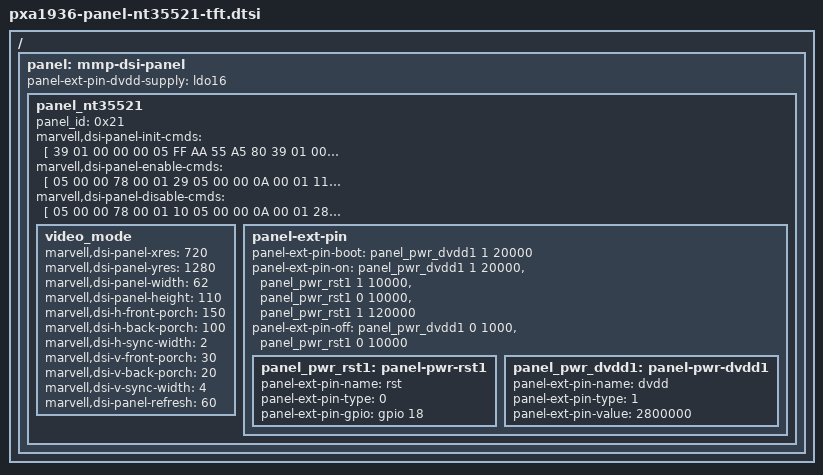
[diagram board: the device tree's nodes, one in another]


/ {
	panel: mmp-dsi-panel {
		panel-ext-pin-dvdd-supply = <&ldo16>;
		panel_nt35521 {
			/*
			 * BACKLIGHT CONTROL BY GPIO
			 */
			panel_id = <0x21>;
			/*
			 * DSI PACKET HEADER INFO
			 * @ data type : 1byte
			 * @ command type : 1byte
			 * @ delay(msec) : 2byte
			 * @ size of data : 2byte
			 */
			marvell,dsi-panel-init-cmds = [
	#if 0 
                            39 01 00 00 00 05 FF AA 55 A5 80                                                              
                            39 01 00 00 00 03 6F 11 00                                                                     
                            39 01 00 00 00 03 F7 20 00                                                                     
                            39 01 00 00 00 02 6F 1E                                                                        
                            39 01 00 00 00 02 FA 20                                                                        
                            39 01 00 00 00 02 6F 1E                                                                        
                            39 01 00 00 00 02 FA 00                                                                        
                            39 01 00 00 00 02 6F 1F                                                                        
                            39 01 00 00 00 02 FA 00                                                                        
                            39 01 00 00 00 02 6F 11                                                                        
                            39 01 00 00 00 02 F3 01                                                                        
                            39 01 00 00 00 06 F0 55 AA 52 08 00                                                          
                            39 01 00 00 00 06 BD 01 A0 0C 08 01                                                          
                            39 01 00 00 00 02 6F 02                                                                      
                            39 01 00 00 00 02 B8 01                                                                  
                            39 01 00 00 00 03 B1 68 21                                                                   
                            39 01 00 00 00 03 BB 11 11                                                                   
                            39 01 00 00 00 03 BC 00 00                                                                   
                            39 01 00 00 00 02 B6 01                                                                     
                            39 01 00 00 00 06 F0 55 AA 52 08 01                                                         
                            39 01 00 00 00 03 B0 09 09                                                                   
                            39 01 00 00 00 03 B1 09 09                                                                   
                            39 01 00 00 00 03 BC 68 00                                                                   
                            39 01 00 00 00 03 BD 68 00                                                                   
                            39 01 00 00 00 02 CA 00                                                                      
                            39 01 00 00 00 02 C0 04                                                                      
                            39 01 00 00 00 03 B5 03 03                                                                  
                            39 01 00 00 00 02 BE 53                                                           
                            39 01 00 00 00 03 B3 19 19                                                                   
                            39 01 00 00 00 03 B4 0F 0F                                                                   
                            39 01 00 00 00 03 B9 26 26
                            39 01 00 00 00 03 BA 14 14
                            39 01 00 00 00 06 F0 55 AA 52 08 02                                                         
                            39 01 00 00 00 02 EE 01
                            39 01 00 00 00 11 B0 00 00 00 58 00 88 00 A7 00 C0 00 E8 01 08 01 3C   
                            39 01 00 00 00 11 B1 01 63 01 A4 01 D6 02 26 02 67 02 69 02 A5 02 E3   
                            39 01 00 00 00 11 B2 03 09 03 3A 03 5E 03 8A 03 A5 03 C4 03 D8 03 ED   
                            39 01 00 00 00 05 B3 03 F7 03 FB                                                             
                            39 01 00 00 00 02 6F 02                                                                      
                            39 01 00 00 00 02 F7 47                                                                      
                            39 01 00 00 00 02 6F 0A                                                                      
                            39 01 00 00 00 02 F7 02                                                                      
                            39 01 00 00 00 02 6F 17                                                                      
                            39 01 00 00 00 02 F4 70                                                                      
                            39 01 00 00 00 02 6F 11                                                                      
                            39 01 00 00 00 02 F3 01
                            39 01 00 00 00 06 F0 55 AA 52 08 06                                                         
                            39 01 00 00 00 03 B0 12 10                                                                 
                            39 01 00 00 00 03 B1 18 16                                                                 
                            39 01 00 00 00 03 B2 00 02                                                                 
                            39 01 00 00 00 03 B3 31 31                                                                 
                            39 01 00 00 00 03 B4 31 34                                                                 
                            39 01 00 00 00 03 B5 34 31                                                                 
                            39 01 00 00 00 03 B6 31 33                                                                 
                            39 01 00 00 00 03 B7 33 33                                                                 
                            39 01 00 00 00 03 B8 31 08                                                                 
                            39 01 00 00 00 03 B9 2E 2D                                                                 
                            39 01 00 00 00 03 BA 2D 2E                                                                 
                            39 01 00 00 00 03 BB 09 31                                                                 
                            39 01 00 00 00 03 BC 33 33                                                                 
                            39 01 00 00 00 03 BD 33 31                                                                 
                            39 01 00 00 00 03 BE 31 34                                                                 
                            39 01 00 00 00 03 BF 34 31                                                                 
                            39 01 00 00 00 03 C0 31 31                                                                 
                            39 01 00 00 00 03 C1 03 01                                                                 
                            39 01 00 00 00 03 C2 17 19                                                                 
                            39 01 00 00 00 03 C3 11 13                                                                 
                            39 01 00 00 00 03 E5 31 31                                                                 
                            39 01 00 00 00 03 C4 17 19                                                                 
                            39 01 00 00 00 03 C5 11 13                                                                 
                            39 01 00 00 00 03 C6 03 01                                                                 
                            39 01 00 00 00 03 C7 31 31                                                                 
                            39 01 00 00 00 03 C8 31 34                                                                 
                            39 01 00 00 00 03 C9 34 31                                                                 
                            39 01 00 00 00 03 CA 31 33                                                                 
                            39 01 00 00 00 03 CB 33 33                                                                 
                            39 01 00 00 00 03 CC 31 09                                                                 
                            39 01 00 00 00 03 CD 2D 2E                                                                 
                            39 01 00 00 00 03 CE 2E 2D                                                                 
                            39 01 00 00 00 03 CF 08 31                                                                 
                            39 01 00 00 00 03 D0 33 33                                                                 
                            39 01 00 00 00 03 D1 33 31                                                                 
                            39 01 00 00 00 03 D2 31 34                                                                 
                            39 01 00 00 00 03 D3 34 31                                                                 
                            39 01 00 00 00 03 D4 31 31                                                                 
                            39 01 00 00 00 03 D5 00 02                                                                 
                            39 01 00 00 00 03 D6 12 10                                                                 
                            39 01 00 00 00 03 D7 18 16                                                                 
                            39 01 00 00 00 06 D8 00 00 00 00 00                                                          
                            39 01 00 00 00 06 D9 00 00 00 00 00                                                          
                            39 01 00 00 00 02 E7 00
                            39 01 00 00 00 06 F0 55 AA 52 08 05                                                         
                            39 01 00 00 00 02 ED 30
                            39 01 00 00 00 06 F0 55 AA 52 08 03                                                         
                            39 01 00 00 00 03 B1 00 00                                                                   
                            39 01 00 00 00 03 B0 00 00
                            39 01 00 00 00 06 F0 55 AA 52 08 05                                                          
                            39 01 00 00 00 02 E5 00                                                                  
                            39 01 00 00 00 06 F0 55 AA 52 08 05                                                         
                            39 01 00 00 00 03 B0 17 06                                                                  
                            39 01 00 00 00 02 B8 00                                                                     
                            39 01 00 00 00 06 BD 03 03 01 00 03                                                         
                            39 01 00 00 00 03 B1 17 06                                                                   
                            39 01 00 00 00 03 B9 00 03                                                                   
                            39 01 00 00 00 03 B2 17 06                                                                   
                            39 01 00 00 00 03 BA 00 00                                                                   
                            39 01 00 00 00 03 B3 17 06                                                                   
                            39 01 00 00 00 03 BB 00 00                                                                   
                            39 01 00 00 00 03 B4 17 06                                                                   
                            39 01 00 00 00 03 B5 17 06                                                                   
                            39 01 00 00 00 03 B6 17 06                                                                   
                            39 01 00 00 00 03 B7 17 06                                                                   
                            39 01 00 00 00 03 BC 00 03                                                                   
                            39 01 00 00 00 02 E5 06                                                                      
                            39 01 00 00 00 02 E6 06                                                                      
                            39 01 00 00 00 02 E7 06                                                                      
                            39 01 00 00 00 02 E8 06                                                                      
                            39 01 00 00 00 02 E9 06                                                                      
                            39 01 00 00 00 02 EA 06                                                                      
                            39 01 00 00 00 02 EB 06                                                                      
                            39 01 00 00 00 02 EC 06
                            39 01 00 00 00 06 F0 55 AA 52 08 05                                                         
                            39 01 00 00 00 02 C0 0B                                                                  
                            39 01 00 00 00 02 C1 09                                                                  
                            39 01 00 00 00 02 C2 0B                                                                    
                            39 01 00 00 00 02 C3 09
                            39 01 00 00 00 06 F0 55 AA 52 08 03                                                          
                            39 01 00 00 00 06 B2 05 00 00 00 90                                        
                            39 01 00 00 00 06 B3 05 00 00 00 90                                                          
                            39 01 00 00 00 06 B4 05 00 00 00 90                                                          
                            39 01 00 00 00 06 B5 05 00 00 00 90
                            39 01 00 00 00 06 F0 55 AA 52 08 05                                                          
                            39 01 00 00 00 02 C4 10                                                                      
                            39 01 00 00 00 02 C5 10                                                                      
                            39 01 00 00 00 02 C6 10                                                                      
                            39 01 00 00 00 02 C7 10
                            39 01 00 00 00 06 F0 55 AA 52 08 03                                                          
                            39 01 00 00 00 06 B6 05 00 00 00 00                                       
                            39 01 00 00 00 06 B7 05 00 00 00 00                                                          
                            39 01 00 00 00 06 B8 05 00 00 00 00                                                          
                            39 01 00 00 00 06 B9 05 00 00 00 00
                            39 01 00 00 00 06 F0 55 AA 52 08 05                                                          
                            39 01 00 00 00 03 C8 07 20                                                                   
                            39 01 00 00 00 03 C9 03 20                                                                   
                            39 01 00 00 00 03 CA 07 00                                                                   
                            39 01 00 00 00 03 CB 03 00
                            39 01 00 00 00 06 F0 55 AA 52 08 03                                                          
                            39 01 00 00 00 06 BA 44 00 00 00 70                                
                            39 01 00 00 00 06 BB 44 00 00 00 70                                                     
                            39 01 00 00 00 06 BC 44 00 00 00 70                                                      
                            39 01 00 00 00 06 BD 44 00 00 00 70
                            39 01 00 00 00 06 F0 55 AA 52 08 05                                                          
                            39 01 00 00 00 06 D1 00 05 00 07 10                                                          
                            39 01 00 00 00 06 D2 00 05 04 07 10                                                          
                            39 01 00 00 00 06 D3 00 00 0A 07 10                                                          
                            39 01 00 00 00 06 D4 00 00 0A 07 10
                            39 01 00 00 00 06 F0 55 AA 52 08 05                                                          
                            39 01 00 00 00 08 D0 00 00 00 00 00 00 00                                               
                            39 01 00 00 00 0C D5 00 00 00 00 00 00 00 00 00 00 00                            
                            39 01 00 00 00 0C D6 00 00 00 00 00 00 00 00 00 00 00                            
                            39 01 00 00 00 0C D7 00 00 00 00 00 00 00 00 00 00 00                            
                            39 01 00 00 00 06 D8 00 00 00 00 00
                            39 01 00 00 00 06 F0 55 AA 52 08 03                                                          
                            39 01 00 00 00 02 C4 60                                                                              
                            39 01 00 00 00 02 C5 40                                                                              
                            39 01 00 00 00 02 C6 60                                                                              
                            39 01 00 00 00 02 C7 40                                                                              
                            39 01 00 00 00 02 6F 01                                                                              
                            39 01 00 00 00 02 F9 46                                                                              
                            39 01 00 00 00 02 35 00                                                                              
                            39 01 00 00 00 02 55 90
#endif
#if 1 
				39 01 00 00 00 05 FF AA 55 A5 80
				39 01 00 00 00 03 6F 11 00
				39 01 00 00 00 03 F7 20 00
				39 01 00 00 00 02 6F 11
				39 01 00 00 00 02 F3 01
				39 01 00 00 00 06 F0 55 AA 52 08 00
				39 01 00 00 00 06 BD 01 A0 0C 08 01
				39 01 00 00 00 02 6F 02
				39 01 00 00 00 02 B8 01
				39 01 00 00 00 03 BB 11 11
				39 01 00 00 00 03 BC 00 00
				39 01 00 00 00 02 B6 06
				39 01 00 00 00 06 F0 55 AA 52 08 01
				39 01 00 00 00 03 B0 09 09
				39 01 00 00 00 03 B1 09 09
				39 01 00 00 00 03 BC 78 00
				39 01 00 00 00 03 BD 78 00
				39 01 00 00 00 02 C0 04
				39 01 00 00 00 03 B5 03 03
				39 01 00 00 00 02 BE 53
				39 01 00 00 00 03 B3 20 20
				39 01 00 00 00 03 B4 0F 0F
				39 01 00 00 00 03 B9 34 34
				39 01 00 00 00 03 BA 15 15
				39 01 00 00 00 06 F0 55 AA 52 08 02
				39 01 00 00 00 02 EE 01
				39 01 00 00 00 11 B0 00 00 00 58 00 88 00 A7 00 C0 00 E8 01 08 01 3C
				39 01 00 00 00 11 B1 01 63 01 A4 01 D6 02 26 02 67 02 69 02 A5 02 E3
				39 01 00 00 00 11 B2 03 09 03 3A 03 5E 03 8A 03 A5 03 C4 03 D8 03 ED
				39 01 00 00 00 05 B3 03 F7 03 FB
				39 01 00 00 00 02 6F 02
				39 01 00 00 00 02 F7 47
				39 01 00 00 00 02 6F 0A
				39 01 00 00 00 02 F7 02
				39 01 00 00 00 02 6F 17
				39 01 00 00 00 02 F4 60
				39 01 00 00 00 02 6F 29
				39 01 00 00 00 02 FA 01
				39 01 00 00 00 02 6F 11
				39 01 00 00 00 02 F3 01
				39 01 00 00 00 06 F0  55 AA 52 08 06
				39 01 00 00 00 03 B0  12 10
				39 01 00 00 00 03 B1  18 16
				39 01 00 00 00 03 B2  00 02
				39 01 00 00 00 03 B3  31 31
				39 01 00 00 00 03 B4  31 31
				39 01 00 00 00 03 B5  31 31
				39 01 00 00 00 03 B6  31 31
				39 01 00 00 00 03 B7  31 31
				39 01 00 00 00 03 B8  31 08
				39 01 00 00 00 03 B9  2E 2D
				39 01 00 00 00 03 BA  2D 2E
				39 01 00 00 00 03 BB  09 31
				39 01 00 00 00 03 BC  31 31
				39 01 00 00 00 03 BD  31 31
				39 01 00 00 00 03 BE  31 31
				39 01 00 00 00 03 BF  31 31
				39 01 00 00 00 03 C0  31 31
				39 01 00 00 00 03 C1  03 01
				39 01 00 00 00 03 C2  17 19
				39 01 00 00 00 03 C3  11 13
				39 01 00 00 00 03 E5  31 31
				39 01 00 00 00 03 C4  17 19
				39 01 00 00 00 03 C5  11 13
				39 01 00 00 00 03 C6  03 01
				39 01 00 00 00 03 C7  31 31
				39 01 00 00 00 03 C8  31 31
				39 01 00 00 00 03 C9  31 31
				39 01 00 00 00 03 CA  31 31
				39 01 00 00 00 03 CB  31 31
				39 01 00 00 00 03 CC  31 09
				39 01 00 00 00 03 CE  2E 2D
				39 01 00 00 00 03 CF  08 31
				39 01 00 00 00 03 D0  31 31
				39 01 00 00 00 03 D1  31 31
				39 01 00 00 00 03 D2  31 31
				39 01 00 00 00 03 D3  31 31
				39 01 00 00 00 03 D4  31 31
				39 01 00 00 00 03 D5  00 02
				39 01 00 00 00 03 D6  12 10
				39 01 00 00 00 03 D7  18 16
				39 01 00 00 00 06 D8  00 00 00 00 00
				39 01 00 00 00 06 D9  00 00 00 00 00
				39 01 00 00 00 02 E7  00
				39 01 00 00 00 06 F0  55 AA 52 08 05
				39 01 00 00 00 02 ED  30
				39 01 00 00 00 06 F0  55 AA 52 08 03
				39 01 00 00 00 03 B1  00 00
				39 01 00 00 00 03 B0  20 00
				39 01 00 00 00 06 F0  55 AA 52 08 05
				39 01 00 00 00 02 E5  00
				39 01 00 00 00 06 F0  55 AA 52 08 05
				39 01 00 00 00 03 B0  17 06
				39 01 00 00 00 02 B8  00
				39 01 00 00 00 06 BD  03 03 01 00 03
				39 01 00 00 00 03 B1  17 06
				39 01 00 00 00 03 B9  00 03
				39 01 00 00 00 03 B2  17 06
				39 01 00 00 00 03 BA  00 00
				39 01 00 00 00 03 B3  17 06
				39 01 00 00 00 03 BB  00 00
				39 01 00 00 00 03 B4  17 06
				39 01 00 00 00 03 B5  17 06
				39 01 00 00 00 03 B6  17 06
				39 01 00 00 00 03 B7  17 06
				39 01 00 00 00 03 BC  00 03
				39 01 00 00 00 02 E5  06
				39 01 00 00 00 02 E6  06
				39 01 00 00 00 02 E7  06
				39 01 00 00 00 02 E8  06
				39 01 00 00 00 02 E9  06
				39 01 00 00 00 02 EA  06
				39 01 00 00 00 02 EB  06
				39 01 00 00 00 02 EC  06
				39 01 00 00 00 06 F0  55 AA 52 08 05
				39 01 00 00 00 02 C0  0B
				39 01 00 00 00 02 C1  09
				39 01 00 00 00 02 C2  0B
				39 01 00 00 00 02 C3  09
				39 01 00 00 00 06 F0  55 AA 52 08 03
				39 01 00 00 00 06 B2  05 00 00 00 90
				39 01 00 00 00 06 B3  05 00 00 00 90
				39 01 00 00 00 06 B4  05 00 00 00 90
				39 01 00 00 00 06 B5  05 00 00 00 90
				39 01 00 00 00 06 F0  55 AA 52 08 05
				39 01 00 00 00 02 C4  10
				39 01 00 00 00 02 C5  10
				39 01 00 00 00 02 C6  10
				39 01 00 00 00 02 C7  10
				39 01 00 00 00 06 F0  55 AA 52 08 03
				39 01 00 00 00 06 B6  05 00 00 00 90
				39 01 00 00 00 06 B7  05 00 00 00 90
				39 01 00 00 00 06 B8  05 00 00 00 90
				39 01 00 00 00 06 B9  05 00 00 00 90
				39 01 00 00 00 06 F0  55 AA 52 08 05
				39 01 00 00 00 03 C8  08 20
				39 01 00 00 00 03 C9  04 20
				39 01 00 00 00 03 CA  07 00
				39 01 00 00 00 03 CB  03 00
				39 01 00 00 00 06 F0  55 AA 52 08 03
				39 01 00 00 00 06 BA  53 01 00 01 00
				39 01 00 00 00 06 BB  53 01 00 01 00
				39 01 00 00 00 06 BC  53 01 00 01 00
				39 01 00 00 00 06 BD  53 01 00 01 00
				39 01 00 00 00 06 F0  55 AA 52 08 05
				39 01 00 00 00 06 D1  00 05 00 07 10
				39 01 00 00 00 06 D2  00 05 04 07 10
				39 01 00 00 00 06 D3  00 00 0A 07 10
				39 01 00 00 00 06 D4  00 00 0A 07 10
				39 01 00 00 00 06 F0  55 AA 52 08 05
				39 01 00 00 00 08 D0  00 00 00 00 00 00 00
				39 01 00 00 00 0c D5  00 00 00 00 00 00 00 00 00 00 00
				39 01 00 00 00 0c D6  00 00 00 00 00 00 00 00 00 00 00
				39 01 00 00 00 0c D7  00 00 00 00 00 00 00 00 00 00 00
				39 01 00 00 00 06 D8  00 00 00 00 00
				39 01 00 00 00 06 F0  55 AA 52 08 03
				39 01 00 00 00 02 C4  60
				39 01 00 00 00 02 C5  40
				39 01 00 00 00 02 C6  60
				39 01 00 00 00 02 C7  40
				39 01 00 00 00 02 6F 01
				39 01 00 00 00 02 F9 46
				39 01 00 00 00 06 F0  55 AA 52 08 00
				39 01 00 00 00 03 D9  02 05
#endif
			];
			marvell,dsi-panel-enable-cmds = [
			    05 00 00 78 00 01 29
			    05 00 00 0A 00 01 11
			];	
			marvell,dsi-panel-disable-cmds = [
			    05 00 00 78 00 01 10
			    05 00 00 0A 00 01 28
			];
			video_mode {
				marvell,dsi-panel-xres = <720>;
				marvell,dsi-panel-yres = <1280>;
				marvell,dsi-panel-width= <62>;      /* screen width in mm */
				marvell,dsi-panel-height = <110>;    /* screen height in mm */
				marvell,dsi-h-front-porch = <150>;   /* right margin */
				marvell,dsi-h-back-porch = <100>;    /* left margin */
				marvell,dsi-h-sync-width = <2>;    /* hsync len */
				marvell,dsi-v-front-porch = <30>;    /* lower margin */
				marvell,dsi-v-back-porch = <20>;    /* upper margin */
				marvell,dsi-v-sync-width = <4>;     /* vsync len */
				marvell,dsi-panel-refresh = <60>;   /* screen fresh */
			};
			panel-ext-pin {
				/*
				 * Three properties are required
				 * to control pwr pin
				 * @node : panel-ext-pin node
				 * @on : <0> - off / <1> - on
				 * @usec : delay time of usec
				 */
				/*
				 * panel-ext-pin-boot sequence
				 * is skip power on mode
				 */
				panel-ext-pin-boot = <
					&panel_pwr_dvdd1  1 20000
					>;
				panel-ext-pin-on = <
					&panel_pwr_dvdd1  1 20000
					&panel_pwr_rst1   1 10000
					&panel_pwr_rst1   0 10000
					&panel_pwr_rst1   1 120000
					>;
				panel-ext-pin-off = <
					&panel_pwr_dvdd1  0 1000
					&panel_pwr_rst1   0 10000
					>;
				/*
				 * There are four properties to define pwr pin
				 * <prefix>-name : pin name
				 * <prefix>-type : <0> - GPIO, <1> - PMIC Regulator
				 * <prefix>-gpio : If the type is GPIO, assign a gpio.
				 * <prefix>-supply : If the type is PMIC Regulator, assign a regulator.
				 */
				panel_pwr_rst1: panel-pwr-rst1 {
					panel-ext-pin-name = "rst";
					panel-ext-pin-type = <0>;
					panel-ext-pin-gpio = <&gpio 18 0>;
				};
				panel_pwr_dvdd1: panel-pwr-dvdd1 {
					panel-ext-pin-name = "dvdd";
					panel-ext-pin-type = <1>;
					panel-ext-pin-value = <2800000>;
				};
			};
		};
	};
};
